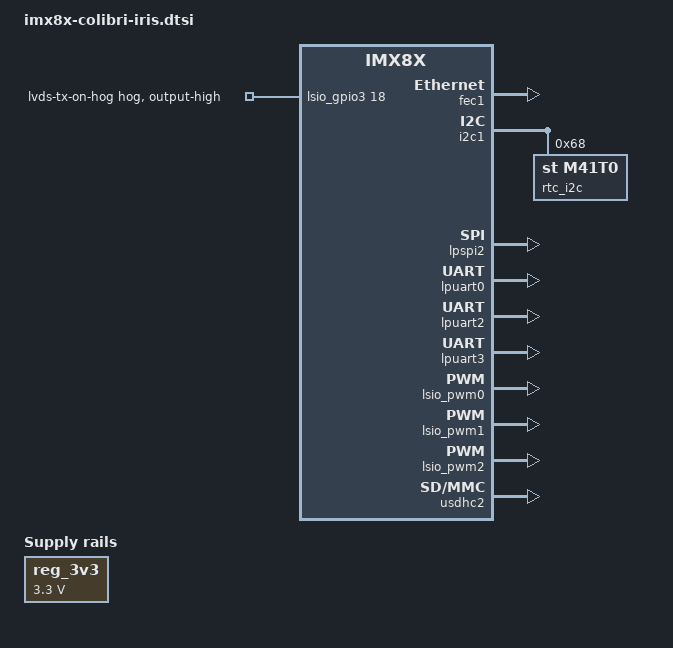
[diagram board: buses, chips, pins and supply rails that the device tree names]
/ {
	aliases {
		rtc0 = &rtc_i2c;
		rtc1 = &rtc;
	};
	reg_3v3: regulator-3v3 {
		compatible = "regulator-fixed";
		regulator-max-microvolt = <3300000>;
		regulator-min-microvolt = <3300000>;
		regulator-name = "3.3V";
	};
};
&colibri_gpio_keys {
	status = "okay";
};
&fec1 {
	status = "okay";
};
&i2c1 {
	status = "okay";
	rtc_i2c: rtc@68 {
		compatible = "st,m41t0";
		reg = <0x68>;
	};
};
&iomuxc {
	pinctrl-names = "default";
	pinctrl-0 = <&pinctrl_gpio_iris>;
	pinctrl_gpio_iris: gpioirisgrp {
		fsl,pins = <IMX8QXP_QSPI0B_DATA3_LSIO_GPIO3_IO21	0x20>,		 
			   <IMX8QXP_USB_SS3_TC1_LSIO_GPIO4_IO04		0x20>,		 
			   <IMX8QXP_SAI0_TXD_LSIO_GPIO0_IO25		0x20>,		 
			   <IMX8QXP_SAI0_TXFS_LSIO_GPIO0_IO28		0x20>,		 
			   <IMX8QXP_SAI0_RXD_LSIO_GPIO0_IO27		0x20>,		 
			   <IMX8QXP_ENET0_RGMII_RXC_LSIO_GPIO5_IO03	0x06000020>,	 
			   <IMX8QXP_SAI0_TXC_LSIO_GPIO0_IO26		0x20>;		 
	};
	pinctrl_uart1_forceoff: uart1forceoffgrp {
		fsl,pins = <IMX8QXP_QSPI0A_SS0_B_LSIO_GPIO3_IO14	0x20>;	 
	};
	pinctrl_uart23_forceoff: uart23forceoffgrp {
		fsl,pins = <IMX8QXP_MIPI_DSI1_GPIO0_01_LSIO_GPIO2_IO00	0x20>;  
	};
};
&lpspi2 {
	status = "okay";
};
&lpuart0 {
	status = "okay";
};
&lpuart2 {
	status = "okay";
};
&lpuart3 {
	status = "okay";
};
&lsio_gpio3 {
	lvds-tx-on-hog {
		gpio-hog;
		gpios = <18 0>;
		output-high;
	};
};
&lsio_pwm0 {
	status = "okay";
};
&lsio_pwm1 {
	status = "okay";
};
&lsio_pwm2 {
	status = "okay";
};
&usdhc2 {
	status = "okay";
};
